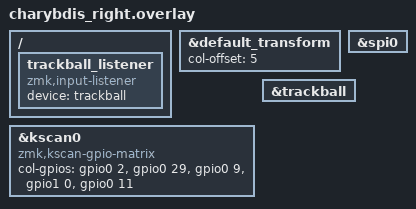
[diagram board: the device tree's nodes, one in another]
#include "charybdis.dtsi"
#include "charybdis_pmw3610.dtsi"

&default_transform {
	col-offset = <5>;
};

&kscan0 {
	compatible = "zmk,kscan-gpio-matrix";
	
	col-gpios
		= <&gpio0 2 (GPIO_ACTIVE_HIGH | GPIO_PULL_DOWN)>
        , <&gpio0 29 (GPIO_ACTIVE_HIGH | GPIO_PULL_DOWN)>
        , <&gpio0 9 (GPIO_ACTIVE_HIGH | GPIO_PULL_DOWN)>
        , <&gpio1 0  (GPIO_ACTIVE_HIGH | GPIO_PULL_DOWN)>
        , <&gpio0 11 (GPIO_ACTIVE_HIGH | GPIO_PULL_DOWN)>
		;
};

&spi0 {
    status = "okay";
};

&trackball {
    status = "okay";
};

// https://github.com/badjeff/zmk-pmw3610-driver
/ {
  trackball_listener {
    compatible = "zmk,input-listener";
    device = <&trackball>;
  };
};
